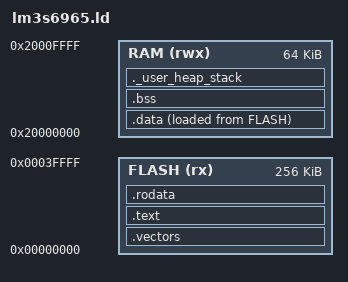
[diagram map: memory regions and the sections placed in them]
/* ==============================================================================
 * lm3s6965.ld — Linker Script for TI Stellaris LM3S6965 (ARM Cortex-M3)
 * Flash: 256 KB (0x00000000 - 0x00040000)
 * SRAM:   64 KB (0x20000000 - 0x20010000)
 * ============================================================================== */

ENTRY(Reset_Handler)

MEMORY
{
    FLASH (rx) : ORIGIN = 0x00000000, LENGTH = 256K
    RAM  (rwx) : ORIGIN = 0x20000000, LENGTH = 64K
}

_estack = ORIGIN(RAM) + LENGTH(RAM);    /* Top of 64 KB SRAM (0x20010000) */
_min_stack = 2K;                        /* Reserve at least 2 KB for call stack */

SECTIONS
{
    /* Vector table at base of Flash */
    .vectors :
    {
        . = ALIGN(4);
        KEEP(*(.vectors))
        . = ALIGN(4);
    } > FLASH

    /* Program code and inlined constants */
    .text :
    {
        . = ALIGN(4);
        *(.text)
        *(.text*)
        *(.glue_7)
        *(.glue_7t)
        *(.eh_frame)
        KEEP(*(.init))
        KEEP(*(.fini))
        . = ALIGN(4);
        _etext = .;
    } > FLASH

    /* Read-only data (strings, constants, lookup tables) */
    .rodata :
    {
        . = ALIGN(4);
        *(.rodata)
        *(.rodata*)
        . = ALIGN(4);
    } > FLASH

    /* Initialized data placed in RAM, loaded from Flash */
    _sidata = LOADADDR(.data);

    .data :
    {
        . = ALIGN(4);
        _sdata = .;
        *(.data)
        *(.data*)
        . = ALIGN(4);
        _edata = .;
    } > RAM AT > FLASH

    /* Uninitialized static data (.bss) - strictly zeroed at startup */
    .bss :
    {
        . = ALIGN(4);
        _sbss = .;
        __bss_start__ = _sbss;
        *(.bss)
        *(.bss*)
        *(COMMON)
        . = ALIGN(4);
        _ebss = .;
        __bss_end__ = _ebss;
    } > RAM

    /* Stack guard & validation */
    ._user_heap_stack :
    {
        . = ALIGN(8);
        PROVIDE ( end = . );
        PROVIDE ( _end = . );
        . = . + _min_stack;
        . = ALIGN(8);
    } > RAM

    /* Discard debugging / metadata notes not needed on bare-metal target */
    /DISCARD/ :
    {
        libc.a ( * )
        libm.a ( * )
        libgcc.a ( * )
    }
}
